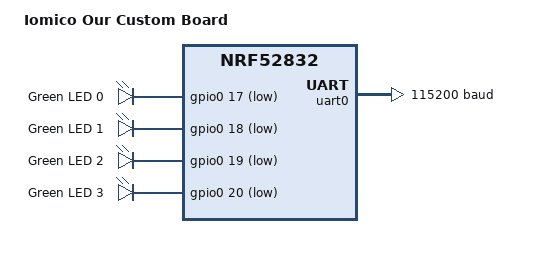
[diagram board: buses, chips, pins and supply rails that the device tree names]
/dts-v1/;

#include <nordic/nrf52832_qfaa.dtsi>
#include "nrf52dk_nrf52832-pinctrl.dtsi"

/ {
	model = "Iomico Our Custom Board";
	compatible = "iomico,our_board_from_scratch_method";

	alises {
		led0 = &led0;
		led1 = &led1;
		led2 = &led2;
		led3 = &led3;
	};

	chosen {
		zephyr,console = &uart0;
		zephyr,sram = &sram0;
		zephyr,flash = &flash0;
		zephyr,code-partition = &slot0_partition;
	};

	leds {
		compatible = "gpio-leds";

		led0: led_0 {
			gpios = <&gpio0 17 GPIO_ACTIVE_LOW>;
			label = "Green LED 0";
		};

		led1: led_1 {
			gpios = <&gpio0 18 GPIO_ACTIVE_LOW>;
			label = "Green LED 1";
		};

		led2: led_2 {
			gpios = <&gpio0 19 GPIO_ACTIVE_LOW>;
			label = "Green LED 2";
		};

		led3: led_3 {
			gpios = <&gpio0 20 GPIO_ACTIVE_LOW>;
			label = "Green LED 3";
		};
	};
};

&gpio0 {
	status = "okay";
};

&gpiote {
	status = "okay";
};

arduino_serial: &uart0 {
	status = "okay";
	compatible = "nordic,nrf-uarte";
	current-speed = <115200>;
	pinctrl-0 = <&uart0_default>;
	pinctrl-1 = <&uart0_sleep>;
	pinctrl-names = "default", "sleep";
};

&flash0 {
	partitions {
		compatible = "fixed-partitions";
		#address-cells = <1>;
		#size-cells = <1>;

		boot_partition: partition@0 {
			label = "mcuboot";
			reg = <0x00000000 0xc000>;
		};

		slot0_partition: partition@c000 {
			label = "image-0";
			reg = <0x0000C000 0x37000>;
		};

		slot1_partition: partition@43000 {
			label = "image-1";
			reg = <0x00043000 0x37000>;
		};

		storage_partition: partition@7a000 {
			label = "storage";
			reg = <0x0007a000 0x00006000>;
		};
	};
};
